# StarFive VisionFive 2 v1.3B register map
File version: 0.1
Registers are 32-bit, read-write, reset 0x0 unless marked. A register's access mark holds for its fields unless they carry their own. Offsets are from the block's base; [hi:lo] are bit positions.

## spi0 — From arm,pl022, peripheral generator
Base 0x10060000
Same registers: spi1 0x10070000, spi2 0x10080000, spi3 0x12070000, spi4 0x12080000, spi5 0x12090000, spi6 0x120A0000
0x00 ssp_cr0 16-bit — SSPCR0 is control register 0 and contains five bit fields that control various functions within the PrimeCell SSP.
  [15:8] scr — Serial clock rate. The value SCR is used to generate the transmit and receive bit rate of the PrimeCell SSP. The bit rate is: (F[sspclk] / (CPSDVR * (1 + SCR))), where CPSDVSR is an even value from [2:254], programmed through the SSPCPSR register and SCR is a value from [0:255]
  [6] spo — SSPCLKOUT polarity, applicable to Motorola SPI frame format only.
  [6] sph — SSPCLKOUT phase, applicable to Motorola SPI frame format only.
  [5:4] frf — Frame format - 00: Motorola SPI frame format, 01: TI synchronous serial frame format, 10: National Microwire frame format, 11: Reserved
  [3:0] dss — Data Size Select - 0000, 0001, 0010: Reserved, 0011: 4-bit data, 0100: 5-bit data, 6-bit data, 0110: 7-bit data, 0111: 8-bit data, 1000: 9-bit data, 1001: 10-bit data, 1010: 11-bit data, 1011: 12-bit data, 1100: 13-bit data, 1101: 14-bit data, 1110: 15-bit data, 1111: 16-bit data
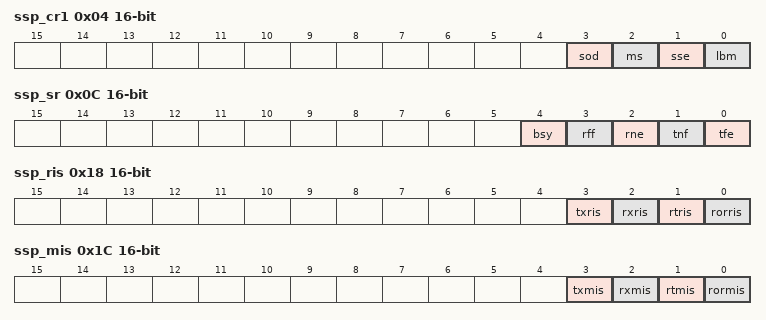
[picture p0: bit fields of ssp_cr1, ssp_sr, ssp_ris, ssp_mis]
0x04 ssp_cr1 16-bit — SSPCR1 is the control register 1 and contains four different bit fields, that control various functions within the PrimeCell SSP.
  [3] sod — Slave-mode output disable. This bit is relevant only in the slave mode, MS=1. In multiple-slave systems, it is possible for an PrimeCell SSP master to broadcast a message to all slaves in the system while ensuring that only one slave drives data onto its serial output line. In such systems the RXD lines from multiple slaves could be tied together. To operate in such systems, the SOD bit can be set if the PrimeCell SSP slave is not supposed to drive the SSPTXD line - 0: SSP can drive the SSPTXD output in slave mode, 1: SSP must not drive the SSPTXD output in slave mode
  [2] ms — Master or slave mode select. This bit can be modified only when the PrimeCell SSP is disabled, SSE=0 - 0: Device configured as master (default), 1: Device configured as slave
  [1] sse — Synchronous serial port enable - 0: SSP operation disabled, 1: SSP operation enabled
  [0] lbm — Loop back mode - 0: Normal serial port operation enabled, 1: Output of transmit serial shifter is connected to input of receive serial shifter internally
0x08 ssp_dr 16-bit — SSPDR is the data register and is 16-bits wide. When SSPDR is read, the entry in the receive FIFO, pointed to by the current FIFO read pointer, is accessed. As data values are removed by the PrimeCell SSP receive logic from the incoming data frame, they are placed into the entry in the receive FIFO, pointed to by the current FIFO write pointer. When SSPDR is written to, the entry in the transmit FIFO, pointed to by the write pointer, is written to. Data values are removed from the transmit FIFO one value at a time by the transmit logic. It is loaded into the transmit serial shifter, then serially shifted out onto the SSPTXD pin at the programmed bit rate. When a data size of less than 16 bits is selected, the user must right-justify data written to the transmit FIFO. The transmit logic ignores the unused bits. Received data less than 16 bits is automatically right-justified in the receive buffer.
  [15:0] data — Transmit/Receive FIFO - Read: Receive FIFO, Write: Transmit FIFO. You must right-justify data when the PrimeCell SSP is programmed for a data size that is less than 16 bits. Unused bits at the top are ignored by transmit logic. The receive logic automatically right-justifies.
0x0C ssp_sr 16-bit — SSPSR is a RO status register that contains bits that indicate the FIFO fill status and the PrimeCell SSP busy status.
  [4] bsy ro — PrimeCell SSP busy flag, RO - 0: SSP is idle, 1: SSP is currently transmitting and/or receiving a frame or the transmit FIFO is not empty.
  [3] rff ro — Receive FIFO full, RO - 0: Receive FIFO is not full, 1: Receive FIFO is full.
  [2] rne ro — Receive FIFO not empty, RO - 0: Receive FIFO is empty, 1: Receive FIFO is not empty.
  [1] tnf ro — Transmit FIFO not full, RO - 0: Transmit FIFO is full, 1: Transmit FIFO is not full.
  [0] tfe ro — Transmit FIFO empty, RO - 0: Transmit FIFO is not empty, 1: Transmit FIFO is empty.
0x10 ssp_cpsr 16-bit — SSPCPSR is the clock prescale register and specifies the division factor by which the input SSPCLK must be internally divided before further use. The value programmed into this register must be an even number between [2:254]. The least significant bit of the programmed number is hard-coded to zero. If an odd number is written to this register, data read back from this register has the least significant bit as zero.
  [7:0] cpsdvsr — Clock prescale divisor. Must be an even number from 2-254, depending on the frequency of SSPCLK. The least significant bit always returns zero on reads.
0x14 ssp_imsc 16-bit — The SSPIMSC register is the interrupt mask set or clear register. It is a RW register. On a read this register gives the current value of the mask on the relevant interrupt. A write of 1 to the particular bit sets the mask, enabling the interrupt to be read. A write of 0 clears the corresponding mask. All the bits are cleared to 0 when reset.
  [2] rxim — Receive FIFO interrupt mask - 0: Receive FIFO half full or less condition interrupt is masked, 1: Receive FIFO half full or less condition interrupt is not masked
  [2] txim — Transmit FIFO interrupt mask - 0: Transmit FIFO half empty or less condition interrupt is masked, 1: Transmit FIFO half empty or less condition interrupt is not masked
  [1] rtim — Receive timeout interrupt mask - 0: Receive FIFO not empty and no read prior to timeout period interrupt is masked, 1: Receive FIFO not empty and no read prior to timeout period interrupt is not masked
  [0] rorim — Receive overrun interrupt mask - 0: Receive FIFO written to while full condition interrupt is masked, 1: Receive FIFO written to while full condition interrupt is not masked
0x18 ssp_ris 16-bit — The SSPRIS register is the raw interrupt status register. It is a RO register. On a read this register gives the current raw status value of the corresponding interrupt prior to masking. A write has no effect.
  [3] txris ro — Gives the raw interrupt state, prior to masking, of the SSPTXINTR interrupt
  [2] rxris ro — Gives the raw interrupt state, prior to masking, of the SSPRXINTR interrupt
  [1] rtris ro — Gives the raw interrupt state, prior to masking, of the SSPRTINTR interrupt
  [0] rorris ro — Gives the raw interrupt state, prior to masking, of the SSPRORINTR interrupt
0x1C ssp_mis 16-bit — The SSPMIS register is the masked interrupt status register. It is a RO register. On a read this register gives the current masked status value of the corresponding interrupt. A write has no effect.
  [3] txmis ro — Gives the transmit FIFO masked interrupt state, after masking, of the SSPTXINTR interrupt
  [2] rxmis ro — Gives the receive FIFO masked interrupt state, after masking, of the SSPRXINTR interrupt
  [1] rtmis ro — Gives the receive timeout masked interrupt state, after masking, of the SSPRTINTR interrupt
  [0] rormis ro — Gives the receive over run masked interrupt status, after masking, of the SSPRORINTR interrupt
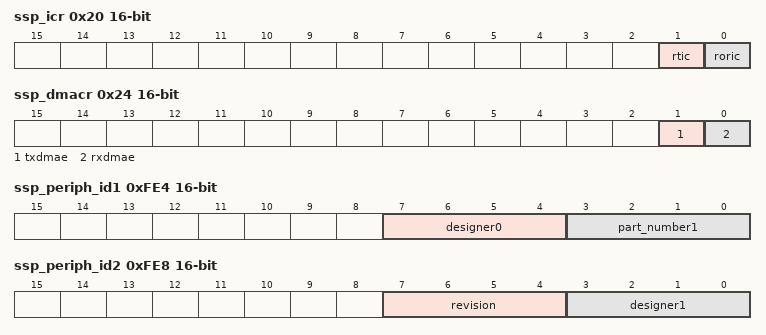
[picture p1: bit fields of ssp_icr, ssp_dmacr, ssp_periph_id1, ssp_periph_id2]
0x20 ssp_icr 16-bit — The SSPICR register is the interrupt clear register and is write-only. On a write of 1, the corresponding interrupt is cleared. A write of 0 has no effect.
  [1] rtic — Clears the SSPRTINTR interrupt
  [0] roric — Clears the SSPRORINTR interrupt
0x24 ssp_dmacr 16-bit — The SSPDMACR register is the DMA control register. It is a RW register. All the bits are cleared to 0 on reset.
  [1] txdmae — Transmit DMA Enable. If this bit is set to 1, DMA for the transmit FIFO is enabled.
  [0] rxdmae — Receive DMA Enable. If this bit is set to 1, DMA for the receive FIFO is enabled.
0xFE0 ssp_periph_id0 16-bit — The SSPPeriphID0 register is hard-coded and the fields within the register determine reset value. The SSPPeriphID0-3 registers are four 8-bit registers, that span address locations 0xFE0 to 0xFEC. The registers can conceptually be treated as a single 32-bit register.
  [7:0] part_number0 ro — These bits read back as 0x22
0xFE4 ssp_periph_id1 16-bit — The SSPPeriphID1 register is hard-coded and the fields within the register determine reset value. The SSPPeriphID0-3 registers are four 8-bit registers, that span address locations 0xFE0 to 0xFEC. The registers can conceptually be treated as a single 32-bit register.
  [7:4] designer0 ro — These bits read back as 0x1
  [3:0] part_number1 ro — These bits read back as 0x0
0xFE8 ssp_periph_id2 16-bit — The SSPPeriphID2 register is hard-coded and the fields within the register determine reset value. The SSPPeriphID0-3 registers are four 8-bit registers, that span address locations 0xFE0 to 0xFEC. The registers can conceptually be treated as a single 32-bit register.
  [7:4] revision ro — These bits return the peripheral revision
  [3:0] designer1 ro — These bits read back as 0x4
0xFEC ssp_periph_id3 16-bit — The SSPPeriphID3 register is hard-coded and the fields within the register determine reset value. The SSPPeriphID0-3 registers are four 8-bit registers, that span address locations 0xFE0 to 0xFEC. The registers can conceptually be treated as a single 32-bit register.
  [7:0] configuration ro — These bits read back as 0x80
0xFF0 ssp_pcell_id0 16-bit — The SSPPCellID0-3 registers are four 8-bit wide registers, that span address locations 0xFF0-0xFFC. The registers can conceptually be treated as a 32-bit register. The register is used as a standard cross-peripheral identification system. The SSPPCellID register is set to 0xB105F00D.
  [7:0] ssp_pcell_id0 ro — The bits are read as 0xD
0xFF4 ssp_pcell_id1 16-bit — The SSPPCellID0-3 registers are four 8-bit wide registers, that span address locations 0xFF0-0xFFC. The registers can conceptually be treated as a 32-bit register. The register is used as a standard cross-peripheral identification system. The SSPPCellID register is set to 0xB105F00D.
  [7:0] ssp_pcell_id1 ro — The bits are read as 0xF0
0xFF8 ssp_pcell_id2 16-bit — The SSPPCellID0-3 registers are four 8-bit wide registers, that span address locations 0xFF0-0xFFC. The registers can conceptually be treated as a 32-bit register. The register is used as a standard cross-peripheral identification system. The SSPPCellID register is set to 0xB105F00D.
  [7:0] ssp_pcell_id2 ro — The bits are read as 0x5
0xFFC ssp_pcell_id3 16-bit — The SSPPCellID0-3 registers are four 8-bit wide registers, that span address locations 0xFF0-0xFFC. The registers can conceptually be treated as a 32-bit register. The register is used as a standard cross-peripheral identification system. The SSPPCellID register is set to 0xB105F00D.
  [7:0] ssp_pcell_id3 ro — The bits are read as 0xB1
